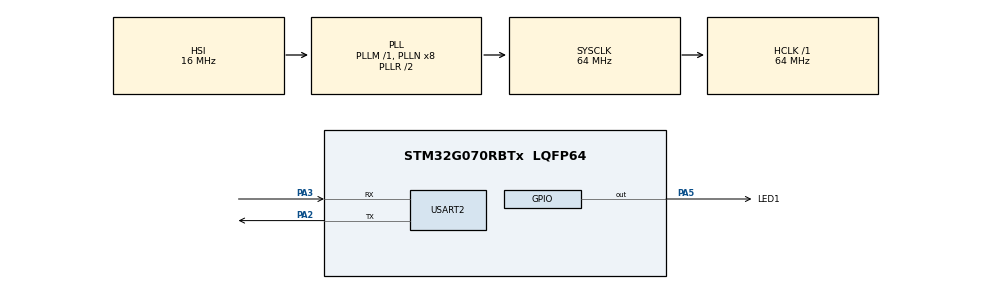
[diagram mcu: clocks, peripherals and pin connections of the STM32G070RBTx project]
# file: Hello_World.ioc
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FREERTOS.BinarySemaphores01=myBinarySem01,Dynamic,NULL
FREERTOS.INCLUDE_vTaskDelayUntil=1
FREERTOS.Queues01=myQueue01,16,uint8_t,0,Dynamic,NULL,NULL
FREERTOS.Tasks01=myTask01,0,128,StartTask01,Default,NULL,Dynamic,NULL,NULL;myTask02,0,128,StartTask02,Default,NULL,Dynamic,NULL,NULL
Mcu.Family=STM32G0
Mcu.Name=STM32G070RBTx
Mcu.Package=LQFP64
NVIC.TIM17_IRQn=true\:3\:0\:false\:false\:true\:false\:false\:true\:true
NVIC.TimeBase=TIM17_IRQn
NVIC.TimeBaseIP=TIM17
PA13.Mode=Serial_Wire
PA13.Signal=SYS_SWDIO
PA14-BOOT0.Mode=Serial_Wire
PA14-BOOT0.Signal=SYS_SWCLK
PA2.Mode=Asynchronous
PA2.Signal=USART2_TX
PA3.Mode=Asynchronous
PA3.Signal=USART2_RX
PA5.GPIO_Label=LED1
PA5.Signal=GPIO_Output
ProjectManager.HeapSize=0x200
ProjectManager.StackSize=0x400
ProjectManager.TargetToolchain=STM32CubeIDE
RCC.ADCFreq_Value=64000000
RCC.AHBFreq_Value=64000000
RCC.CortexFreq_Value=64000000
RCC.EXTERNAL_CLOCK_VALUE=48000
RCC.HCLKFreq_Value=64000000
RCC.HSE_VALUE=8000000
RCC.HSI_VALUE=16000000
RCC.LSE_VALUE=32768
RCC.SYSCLKFreq_VALUE=64000000
RCC.SYSCLKSource=RCC_SYSCLKSOURCE_PLLCLK
RCC.VCOOutputFreq_Value=128000000
USART2.VirtualMode-Asynchronous=VM_ASYNC
VP_FREERTOS_VS_CMSIS_V1.Mode=CMSIS_V1
VP_SYS_VS_tim17.Mode=TIM17
board=custom

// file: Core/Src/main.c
/* USER CODE BEGIN Header */
/**
 ******************************************************************************
 * @file           : main.c
 * @brief          : Main program body
 ******************************************************************************
 * @attention
 *
 * Copyright (c) 2022 STMicroelectronics.
 * All rights reserved.
 *
 * This software is licensed under terms that can be found in the LICENSE file
 * in the root directory of this software component.
 * If no LICENSE file comes with this software, it is provided AS-IS.
 *
 ******************************************************************************
 */
/* USER CODE END Header */
#include "main.h"
#include "cmsis_os.h"
#include "usart.h"
#include "gpio.h"

/* USER CODE BEGIN Includes */
#include "stdio.h"
/* USER CODE END Includes */

void SystemClock_Config(void);
void MX_FREERTOS_Init(void);

int main(void)
{

  /* MCU Configuration--------------------------------------------------------*/

  /* Reset of all peripherals, Initializes the Flash interface and the Systick. */
  HAL_Init();

  /* Configure the system clock */
  SystemClock_Config();

  /* Initialize all configured peripherals */
  MX_GPIO_Init();
  MX_USART2_UART_Init();

  /* Call init function for freertos objects (in freertos.c) */
  MX_FREERTOS_Init();

  /* Start scheduler */
  osKernelStart();

  /* We should never get here as control is now taken by the scheduler */
  /* Infinite loop */
  /* USER CODE BEGIN WHILE */
	while (1)
	{
		HAL_GPIO_TogglePin(LED1_GPIO_Port,LED1_Pin);
		printf("teste \r\n");
		HAL_Delay(1000);
    /* USER CODE END WHILE */

	}
}

void SystemClock_Config(void)
{
  RCC_OscInitTypeDef RCC_OscInitStruct = {0};
  RCC_ClkInitTypeDef RCC_ClkInitStruct = {0};

  /** Configure the main internal regulator output voltage
  */
  HAL_PWREx_ControlVoltageScaling(PWR_REGULATOR_VOLTAGE_SCALE1);

  /** Initializes the RCC Oscillators according to the specified parameters
  * in the RCC_OscInitTypeDef structure.
  */
  RCC_OscInitStruct.OscillatorType = RCC_OSCILLATORTYPE_HSI;
  RCC_OscInitStruct.HSIState = RCC_HSI_ON;
  RCC_OscInitStruct.HSIDiv = RCC_HSI_DIV1;
  RCC_OscInitStruct.HSICalibrationValue = RCC_HSICALIBRATION_DEFAULT;
  RCC_OscInitStruct.PLL.PLLState = RCC_PLL_ON;
  RCC_OscInitStruct.PLL.PLLSource = RCC_PLLSOURCE_HSI;
  RCC_OscInitStruct.PLL.PLLM = RCC_PLLM_DIV1;
  RCC_OscInitStruct.PLL.PLLN = 8;
  RCC_OscInitStruct.PLL.PLLP = RCC_PLLP_DIV2;
  RCC_OscInitStruct.PLL.PLLR = RCC_PLLR_DIV2;
  if (HAL_RCC_OscConfig(&RCC_OscInitStruct) != HAL_OK)
  {
    Error_Handler();
  }

  /** Initializes the CPU, AHB and APB buses clocks
  */
  RCC_ClkInitStruct.ClockType = RCC_CLOCKTYPE_HCLK|RCC_CLOCKTYPE_SYSCLK
                              |RCC_CLOCKTYPE_PCLK1;
  RCC_ClkInitStruct.SYSCLKSource = RCC_SYSCLKSOURCE_PLLCLK;
  RCC_ClkInitStruct.AHBCLKDivider = RCC_SYSCLK_DIV1;
  RCC_ClkInitStruct.APB1CLKDivider = RCC_HCLK_DIV1;

  if (HAL_RCC_ClockConfig(&RCC_ClkInitStruct, FLASH_LATENCY_2) != HAL_OK)
  {
    Error_Handler();
  }
}

/* USER CODE BEGIN 4 */
int __io_putchar(uint8_t ch)
{
	HAL_UART_Transmit(&huart2, (uint8_t *)&ch, 1, HAL_MAX_DELAY);
	return ch;
}
/* USER CODE END 4 */

void HAL_TIM_PeriodElapsedCallback(TIM_HandleTypeDef *htim)
{
  if (htim->Instance == TIM17) {
    HAL_IncTick();
  }
}

void Error_Handler(void)
{
	__disable_irq();
	while (1)
	{
	}
}

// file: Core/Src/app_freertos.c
/* USER CODE BEGIN Header */
/**
 ******************************************************************************
 * File Name          : app_freertos.c
 * Description        : Code for freertos applications
 ******************************************************************************
 * @attention
 *
 * Copyright (c) 2022 STMicroelectronics.
 * All rights reserved.
 *
 * This software is licensed under terms that can be found in the LICENSE file
 * in the root directory of this software component.
 * If no LICENSE file comes with this software, it is provided AS-IS.
 *
 ******************************************************************************
 */
/* USER CODE END Header */

#include "FreeRTOS.h"
#include "task.h"
#include "main.h"
#include "cmsis_os.h"

/* USER CODE BEGIN Includes */
#include "stdio.h"
/* USER CODE END Includes */

osThreadId myTask01Handle;
osThreadId myTask02Handle;
osMessageQId myQueue01Handle;
osSemaphoreId myBinarySem01Handle;

void StartTask01(void const * argument);
void StartTask02(void const * argument);

void MX_FREERTOS_Init(void); /* (MISRA C 2004 rule 8.1) */

void MX_FREERTOS_Init(void) {

  /* Create the semaphores(s) */
  /* definition and creation of myBinarySem01 */
  osSemaphoreDef(myBinarySem01);
  myBinarySem01Handle = osSemaphoreCreate(osSemaphore(myBinarySem01), 1);

  /* Create the queue(s) */
  /* definition and creation of myQueue01 */
  osMessageQDef(myQueue01, 16, uint8_t);
  myQueue01Handle = osMessageCreate(osMessageQ(myQueue01), NULL);

  /* Create the thread(s) */
  /* definition and creation of myTask01 */
  osThreadDef(myTask01, StartTask01, osPriorityNormal, 0, 128);
  myTask01Handle = osThreadCreate(osThread(myTask01), NULL);

  /* definition and creation of myTask02 */
  osThreadDef(myTask02, StartTask02, osPriorityNormal, 0, 128);
  myTask02Handle = osThreadCreate(osThread(myTask02), NULL);

}

void StartTask01(void const * argument)
{
  /* USER CODE BEGIN StartTask01 */
//	uint32_t wakeuptime;
	//osPriority priority;
	/* Infinite loop */
	for(;;)
	{
		osDelay(2000);
		printf("Task 1 Release semaphore \r\n");
		osSemaphoreRelease(myBinarySem01Handle);

//		printf("Task 1 \r\n");
//		HAL_Delay(50);
//		osMessagePut(myQueue01Handle, (uint8_t)0x32, 200);
//		printf("Task 1 delay \r\n");
//		HAL_Delay(80);
//		osDelay(1000);

//		printf("Create task 2 \r\n");
//		osThreadDef(myTask02, StartTask02, osPriorityNormal, 0, 128);
//		myTask02Handle = osThreadCreate(osThread(myTask02), NULL);
//		osDelay(1000);

//		wakeuptime = osKernelSysTick();
//		priority = osThreadGetPriority(myTask02Handle);
//		printf("My Task 1 \r\n");
//		osThreadSetPriority(myTask02Handle, priority + 1);
//		HAL_Delay(1000);
//		osDelayUntil(&wakeuptime, 2000);
	}
  /* USER CODE END StartTask01 */
}

void StartTask02(void const * argument)
{
  /* USER CODE BEGIN StartTask02 */
	//osPriority priority;
//	osEvent retvalue;

	/* Infinite loop */
	for(;;)
	{
		osSemaphoreWait(myBinarySem01Handle, 4000);
		printf("Task 2 Synchronized \r\n");

//		printf("Task 2 \r\n");
//		HAL_Delay(50);
//		retvalue = osMessageGet(myQueue01Handle, 4000);
//		printf("%c \r\n", (int)retvalue.value.v);
//		HAL_Delay(50);

//		printf("Delete task 2 \r\n");
//		osThreadTerminate(myTask02Handle);

		// Read priority off current task
//		priority = osThreadGetPriority(NULL);
//		printf("My Task 2 \r\n");
//		osThreadSetPriority(NULL, priority - 2);
	}
  /* USER CODE END StartTask02 */
}
